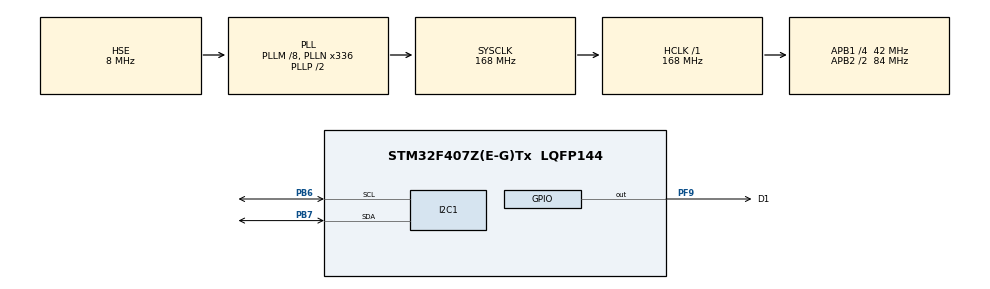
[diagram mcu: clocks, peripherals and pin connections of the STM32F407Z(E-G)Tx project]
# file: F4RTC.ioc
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Mcu.Family=STM32F4
Mcu.Name=STM32F407Z(E-G)Tx
Mcu.Package=LQFP144
NVIC.PriorityGroup=NVIC_PRIORITYGROUP_4
NVIC.RTC_Alarm_IRQn=true\:0\:0\:false\:false\:true\:true\:true
PA13.Mode=Serial_Wire
PA13.Signal=SYS_JTMS-SWDIO
PA14.Mode=Serial_Wire
PA14.Signal=SYS_JTCK-SWCLK
PB6.Mode=I2C
PB6.Signal=I2C1_SCL
PB7.Mode=I2C
PB7.Signal=I2C1_SDA
PC14-OSC32_IN.Mode=LSE-External-Oscillator
PC14-OSC32_IN.Signal=RCC_OSC32_IN
PC15-OSC32_OUT.Mode=LSE-External-Oscillator
PC15-OSC32_OUT.Signal=RCC_OSC32_OUT
PF9.GPIO_Label=D1
PF9.GPIO_Speed=GPIO_SPEED_FREQ_HIGH
PF9.Signal=GPIO_Output
PH0-OSC_IN.Mode=HSE-External-Oscillator
PH0-OSC_IN.Signal=RCC_OSC_IN
PH1-OSC_OUT.Mode=HSE-External-Oscillator
PH1-OSC_OUT.Signal=RCC_OSC_OUT
ProjectManager.HeapSize=0x200
ProjectManager.StackSize=0x400
ProjectManager.TargetToolchain=Makefile
RCC.48MHZClocksFreq_Value=84000000
RCC.AHBFreq_Value=168000000
RCC.APB1CLKDivider=RCC_HCLK_DIV4
RCC.APB1Freq_Value=42000000
RCC.APB1TimFreq_Value=84000000
RCC.APB2CLKDivider=RCC_HCLK_DIV2
RCC.APB2Freq_Value=84000000
RCC.APB2TimFreq_Value=168000000
RCC.CortexFreq_Value=168000000
RCC.HCLKFreq_Value=168000000
RCC.HSE_VALUE=8000000
RCC.HSI_VALUE=16000000
RCC.PLLM=8
RCC.PLLN=336
RCC.PLLSourceVirtual=RCC_PLLSOURCE_HSE
RCC.RCC_RTC_Clock_Source=RCC_RTCCLKSOURCE_LSE
RCC.RCC_RTC_Clock_SourceVirtual=RCC_RTCCLKSOURCE_LSE
RCC.SYSCLKFreq_VALUE=168000000
RCC.SYSCLKSource=RCC_SYSCLKSOURCE_PLLCLK
RCC.VCOOutputFreq_Value=336000000
RTC.Alarm=RTC_ALARM_A
RTC.Date=27
RTC.Hours=14
RTC.Minutes=40
RTC.Month=RTC_MONTH_FEBRUARY
RTC.Seconds_A=10
RTC.StoreOperation=RTC_STOREOPERATION_SET
RTC.WeekDay=RTC_WEEKDAY_THURSDAY
RTC.Year=20
VP_RTC_VS_RTC_Activate.Mode=RTC_Enabled
VP_RTC_VS_RTC_Alarm_A_Intern.Mode=Alarm A
VP_RTC_VS_RTC_Calendar.Mode=RTC_Calendar
VP_RTC_VS_RTC_WakeUp_intern.Mode=WakeUp
board=custom

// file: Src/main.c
/* USER CODE BEGIN Header */
/**
  ******************************************************************************
  * @file           : main.c
  * @brief          : Main program body
  ******************************************************************************
  * @attention
  *
  * <h2><center>&copy; Copyright (c) 2020 STMicroelectronics.
  * All rights reserved.</center></h2>
  *
  * This software component is licensed by ST under BSD 3-Clause license,
  * the "License"; You may not use this file except in compliance with the
  * License. You may obtain a copy of the License at:
  *                        opensource.org/licenses/BSD-3-Clause
  *
  ******************************************************************************
  */
/* USER CODE END Header */

#include "main.h"
#include "i2c.h"
#include "rtc.h"
#include "gpio.h"

/* USER CODE BEGIN Includes */
#include "oleds.h"
#include "stdio.h"
/* USER CODE END Includes */

/* USER CODE BEGIN PTD */
RTC_DateTypeDef sdatestructure;
RTC_TimeTypeDef stimestructure;
/* USER CODE END PTD */

void SystemClock_Config(void);

int main(void)
{
  /* USER CODE BEGIN 1 */
  char buffer[25];
  /* USER CODE END 1 */

  /* MCU Configuration--------------------------------------------------------*/

  /* Reset of all peripherals, Initializes the Flash interface and the Systick. */
  HAL_Init();

  /* Configure the system clock */
  SystemClock_Config();

  /* Initialize all configured peripherals */
  MX_GPIO_Init();
  MX_RTC_Init();
  MX_I2C1_Init();
  /* USER CODE BEGIN 2 */
  OLED_Init();
  OLED_CLS();
  OLED_ShowStr(1,0,(uint8_t *)"Designed by Joe_joe",1);
  /* USER CODE END 2 */

  /* Infinite loop */
  while (1)
  {

    /* USER CODE BEGIN 3 */
    HAL_RTC_GetTime(&hrtc,&stimestructure,RTC_FORMAT_BIN);
    sprintf((char*)buffer,"%02d:%02d:%02d",stimestructure.Hours,stimestructure.Minutes,stimestructure.Seconds);
    OLED_ShowStr(1,1,(uint8_t *)buffer,1);
    HAL_RTC_GetDate(&hrtc,&sdatestructure,RTC_FORMAT_BIN);
    sprintf((char*)buffer,"20%02d:%02d:%02d",sdatestructure.Year,sdatestructure.Month,sdatestructure.Date);
    OLED_ShowStr(1,2,(uint8_t *)buffer,1);
    HAL_GPIO_TogglePin(D1_GPIO_Port, D1_Pin);
    HAL_Delay(1000);
  }
  /* USER CODE END 3 */
}

void SystemClock_Config(void)
{
  RCC_OscInitTypeDef RCC_OscInitStruct = {0};
  RCC_ClkInitTypeDef RCC_ClkInitStruct = {0};
  RCC_PeriphCLKInitTypeDef PeriphClkInitStruct = {0};

  /** Configure the main internal regulator output voltage
  */
  __HAL_RCC_PWR_CLK_ENABLE();
  __HAL_PWR_VOLTAGESCALING_CONFIG(PWR_REGULATOR_VOLTAGE_SCALE1);
  /** Initializes the CPU, AHB and APB busses clocks
  */
  RCC_OscInitStruct.OscillatorType = RCC_OSCILLATORTYPE_HSE|RCC_OSCILLATORTYPE_LSE;
  RCC_OscInitStruct.HSEState = RCC_HSE_ON;
  RCC_OscInitStruct.LSEState = RCC_LSE_ON;
  RCC_OscInitStruct.PLL.PLLState = RCC_PLL_ON;
  RCC_OscInitStruct.PLL.PLLSource = RCC_PLLSOURCE_HSE;
  RCC_OscInitStruct.PLL.PLLM = 8;
  RCC_OscInitStruct.PLL.PLLN = 336;
  RCC_OscInitStruct.PLL.PLLP = RCC_PLLP_DIV2;
  RCC_OscInitStruct.PLL.PLLQ = 4;
  if (HAL_RCC_OscConfig(&RCC_OscInitStruct) != HAL_OK)
  {
    Error_Handler();
  }
  /** Initializes the CPU, AHB and APB busses clocks
  */
  RCC_ClkInitStruct.ClockType = RCC_CLOCKTYPE_HCLK|RCC_CLOCKTYPE_SYSCLK
                              |RCC_CLOCKTYPE_PCLK1|RCC_CLOCKTYPE_PCLK2;
  RCC_ClkInitStruct.SYSCLKSource = RCC_SYSCLKSOURCE_PLLCLK;
  RCC_ClkInitStruct.AHBCLKDivider = RCC_SYSCLK_DIV1;
  RCC_ClkInitStruct.APB1CLKDivider = RCC_HCLK_DIV4;
  RCC_ClkInitStruct.APB2CLKDivider = RCC_HCLK_DIV2;

  if (HAL_RCC_ClockConfig(&RCC_ClkInitStruct, FLASH_LATENCY_5) != HAL_OK)
  {
    Error_Handler();
  }
  PeriphClkInitStruct.PeriphClockSelection = RCC_PERIPHCLK_RTC;
  PeriphClkInitStruct.RTCClockSelection = RCC_RTCCLKSOURCE_LSE;
  if (HAL_RCCEx_PeriphCLKConfig(&PeriphClkInitStruct) != HAL_OK)
  {
    Error_Handler();
  }
}

void Error_Handler(void)
{
}

/************************ (C) COPYRIGHT STMicroelectronics *****END OF FILE****/
